VERSION ""

NS_ :

BS_:

BU_: ADA_B ADCU

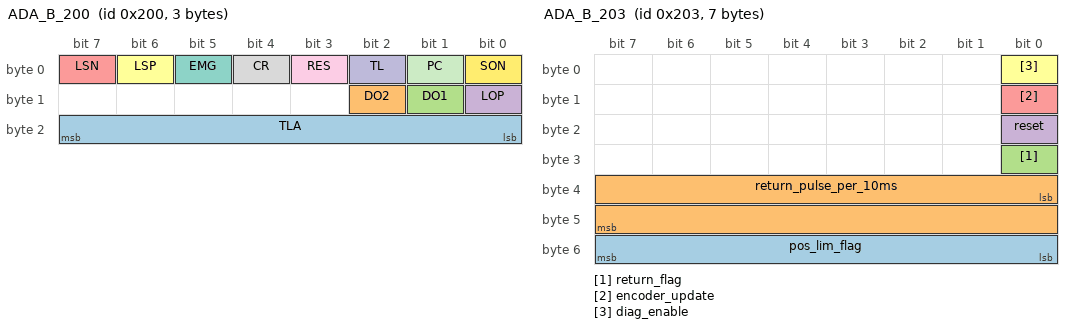
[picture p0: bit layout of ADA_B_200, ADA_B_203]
BO_ 512 ADA_B_200: 3 ADCU
 SG_ TLA : 16|8@1+ (0.39215686274509803,0.0) [0|0] "%" Vector__XXX
 SG_ DO2 : 10|1@1+ (1,0) [0|0] "" Vector__XXX
 SG_ DO1 : 9|1@1+ (1,0) [0|0] "" Vector__XXX
 SG_ LOP : 8|1@1+ (1,0) [0|0] "" Vector__XXX
 SG_ LSN : 7|1@1+ (1,0) [0|0] "" Vector__XXX
 SG_ LSP : 6|1@1+ (1,0) [0|0] "" Vector__XXX
 SG_ EMG : 5|1@1+ (1,0) [0|0] "" Vector__XXX
 SG_ CR : 4|1@1+ (1,0) [0|0] "" Vector__XXX
 SG_ RES : 3|1@1+ (1,0) [0|0] "" Vector__XXX
 SG_ TL : 2|1@1+ (1,0) [0|0] "" Vector__XXX
 SG_ PC : 1|1@1+ (1,0) [0|0] "" Vector__XXX
 SG_ SON : 0|1@1+ (1,0) [0|0] "" Vector__XXX

BO_ 513 ADA_B_201: 4 ADCU
 SG_ target_pos : 0|32@1- (0.01,0.0) [0|0] "mm" Vector__XXX

BO_ 514 ADA_B_202: 4 ADCU
 SG_ pulse : 0|32@1- (1,0) [0|0] "" Vector__XXX

BO_ 515 ADA_B_203: 7 ADCU
 SG_ pos_lim_flag : 48|8@1+ (1,0) [0|0] "" Vector__XXX
 SG_ return_pulse_per_10ms : 32|16@1+ (1,0) [0|0] "" Vector__XXX
 SG_ return_flag : 24|1@1+ (1,0) [0|0] "" Vector__XXX
 SG_ reset : 16|1@1+ (1,0) [0|0] "" Vector__XXX
 SG_ encoder_update : 8|1@1+ (1,0) [0|0] "" Vector__XXX
 SG_ diag_enable : 0|1@1+ (1,0) [0|0] "" Vector__XXX

BO_ 516 ADA_B_204: 8 ADA_B
 SG_ servo_abs_pos : 32|32@1- (0.01,0.0) [0|0] "mm" Vector__XXX
 SG_ encoder_pos : 0|32@1- (0.01,0.0) [0|0] "mm" Vector__XXX

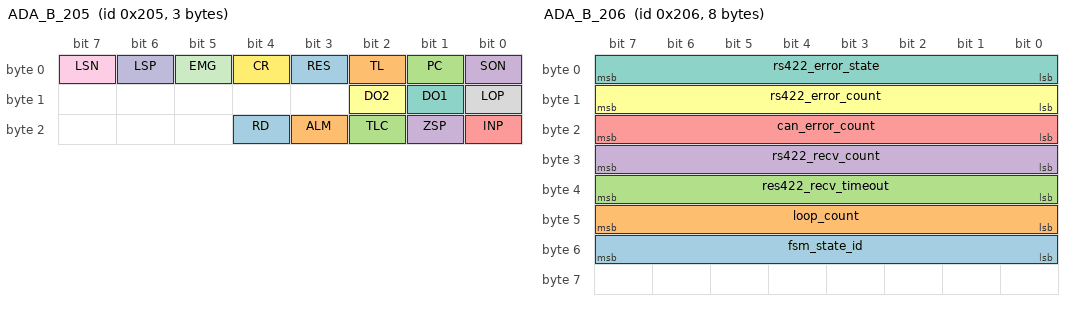
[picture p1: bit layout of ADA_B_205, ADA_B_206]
BO_ 517 ADA_B_205: 3 ADA_B
 SG_ RD : 20|1@1+ (1,0) [0|0] "" Vector__XXX
 SG_ ALM : 19|1@1+ (1,0) [0|0] "" Vector__XXX
 SG_ TLC : 18|1@1+ (1,0) [0|0] "" Vector__XXX
 SG_ ZSP : 17|1@1+ (1,0) [0|0] "" Vector__XXX
 SG_ INP : 16|1@1+ (1,0) [0|0] "" Vector__XXX
 SG_ DO2 : 10|1@1+ (1,0) [0|0] "" Vector__XXX
 SG_ DO1 : 9|1@1+ (1,0) [0|0] "" Vector__XXX
 SG_ LOP : 8|1@1+ (1,0) [0|0] "" Vector__XXX
 SG_ LSN : 7|1@1+ (1,0) [0|0] "" Vector__XXX
 SG_ LSP : 6|1@1+ (1,0) [0|0] "" Vector__XXX
 SG_ EMG : 5|1@1+ (1,0) [0|0] "" Vector__XXX
 SG_ CR : 4|1@1+ (1,0) [0|0] "" Vector__XXX
 SG_ RES : 3|1@1+ (1,0) [0|0] "" Vector__XXX
 SG_ TL : 2|1@1+ (1,0) [0|0] "" Vector__XXX
 SG_ PC : 1|1@1+ (1,0) [0|0] "" Vector__XXX
 SG_ SON : 0|1@1+ (1,0) [0|0] "" Vector__XXX

BO_ 518 ADA_B_206: 8 ADA_B
 SG_ fsm_state_id : 48|8@1+ (1,0) [0|0] "" Vector__XXX
 SG_ loop_count : 40|8@1+ (1,0) [0|0] "" Vector__XXX
 SG_ res422_recv_timeout : 32|8@1+ (1,0) [0|0] "" Vector__XXX
 SG_ rs422_recv_count : 24|8@1+ (1,0) [0|0] "" Vector__XXX
 SG_ can_error_count : 16|8@1+ (1,0) [0|0] "" Vector__XXX
 SG_ rs422_error_count : 8|8@1+ (1,0) [0|0] "" Vector__XXX
 SG_ rs422_error_state : 0|8@1+ (1,0) [0|0] "" Vector__XXX

BO_ 519 ADA_B_207: 8 ADA_B
 SG_ last_backward_pulse : 32|32@1- (1,0) [0|0] "" Vector__XXX
 SG_ last_forward_pulse : 0|32@1- (1,0) [0|0] "" Vector__XXX

BO_ 520 ADA_B_208: 8 ADA_B
 SG_ encoder_offset : 0|32@1- (1,0) [0|0] "" Vector__XXX

BO_ 521 ADA_B_209: 8 ADA_B
 SG_ limit_max : 32|32@1- (1,0) [0|0] "" Vector__XXX
 SG_ limit_min : 0|32@1- (1,0) [0|0] "" Vector__XXX

CM_ SG_ 512 TLA "motor torque limit";
CM_ SG_ 512 DO2 "reserved";
CM_ SG_ 512 DO1 "reserved";
CM_ SG_ 512 LOP "reserved";
CM_ SG_ 512 LSN "reserved";
CM_ SG_ 512 LSP "reserved";
CM_ SG_ 512 EMG "reserved";
CM_ SG_ 512 CR "absolute position clear command";
CM_ SG_ 512 RES "driver reset command";
CM_ SG_ 512 TL "reserved";
CM_ SG_ 512 PC "reserved";
CM_ SG_ 512 SON "actuator enable command(0: stop, 1: stroke control)";
CM_ SG_ 513 target_pos "pedal stroke command";
CM_ SG_ 514 pulse "reserved";
CM_ SG_ 515 pos_lim_flag "min - max position linit enable (0: disable 1: enable)";
CM_ SG_ 515 return_pulse_per_10ms "set return to home speed";
CM_ SG_ 515 return_flag "return to home function enable (0: disable 1: enable)";
CM_ SG_ 515 reset "controller reset";
CM_ SG_ 515 encoder_update "sync absolute position to encoder position";
CM_ SG_ 515 diag_enable "0x106 message activation (0: message off, 1: message on)";
CM_ SG_ 516 servo_abs_pos "pedal stroke feedback (absolute position)";
CM_ SG_ 516 encoder_pos "pedal stroke feedback";
CM_ SG_ 517 RD "driver ready state (0: fault, 1: normal)";
CM_ SG_ 517 ALM "driver warning state (0: fault, 1: normal)";
CM_ SG_ 517 TLC "driver torque limit state (0: normal, 1: max torque)";
CM_ SG_ 517 ZSP "zero speed state (0: motor run, 1: motor stop)";
CM_ SG_ 517 INP "in-position state(0: angle control activate ,1: angle control complete)";
CM_ SG_ 517 DO2 "reserved";
CM_ SG_ 517 DO1 "reserved";
CM_ SG_ 517 LOP "reserved";
CM_ SG_ 517 LSN "reserved";
CM_ SG_ 517 LSP "reserved";
CM_ SG_ 517 EMG "reserved";
CM_ SG_ 517 CR "absolute position clear command monitor";
CM_ SG_ 517 RES "driver reset command monitor";
CM_ SG_ 517 TL "reserved";
CM_ SG_ 517 PC "reserved";
CM_ SG_ 517 SON "actuator enable command monitor";
CM_ SG_ 518 fsm_state_id "controller state / 0: start / 1: wait driver ready / 2: read absolute position  / 3: free wheeing / 4: wait RD on / 5: position control / 6: warning / 7:ReturnToHomePosition / 8:WaitReturnComplete";
CM_ SG_ 518 loop_count "alive counter(rolling counter)";
CM_ SG_ 518 res422_recv_timeout "driver communication timeout error counter";
CM_ SG_ 518 rs422_recv_count "driver communication counter";
CM_ SG_ 518 can_error_count "CAN communication error counter";
CM_ SG_ 518 rs422_error_count "driver communication error counter";
CM_ SG_ 518 rs422_error_state "reserved";
CM_ SG_ 519 last_backward_pulse "reserved";
CM_ SG_ 519 last_forward_pulse "reserved";
CM_ SG_ 520 encoder_offset "reserved";
CM_ SG_ 521 limit_max "set upper limit (pos)";
CM_ SG_ 521 limit_min "set lower limit (pos)";
BA_DEF_ BO_  "GenMsgCycleTime" INT 0 65535;
BA_DEF_ SG_  "GenSigStartValue" FLOAT 0 100000000000;
BA_DEF_DEF_  "GenMsgCycleTime" 0;
BA_DEF_DEF_  "GenSigStartValue" 0.0;
BA_ "GenSigStartValue" SG_ 512 TLA 255;
BA_ "GenSigStartValue" SG_ 512 LSN 1;
BA_ "GenSigStartValue" SG_ 512 LSP 1;
BA_ "GenSigStartValue" SG_ 512 EMG 1;
BA_ "GenMsgCycleTime" BO_ 513 10;
BA_ "GenSigStartValue" SG_ 515 pos_lim_flag 1;
BA_ "GenSigStartValue" SG_ 515 return_pulse_per_10ms 200;
BA_ "GenSigStartValue" SG_ 515 return_flag 1;
BA_ "GenMsgCycleTime" BO_ 516 10;
BA_ "GenMsgCycleTime" BO_ 517 10;
BA_ "GenMsgCycleTime" BO_ 518 10;
BA_ "GenSigStartValue" SG_ 521 limit_max 6000;
